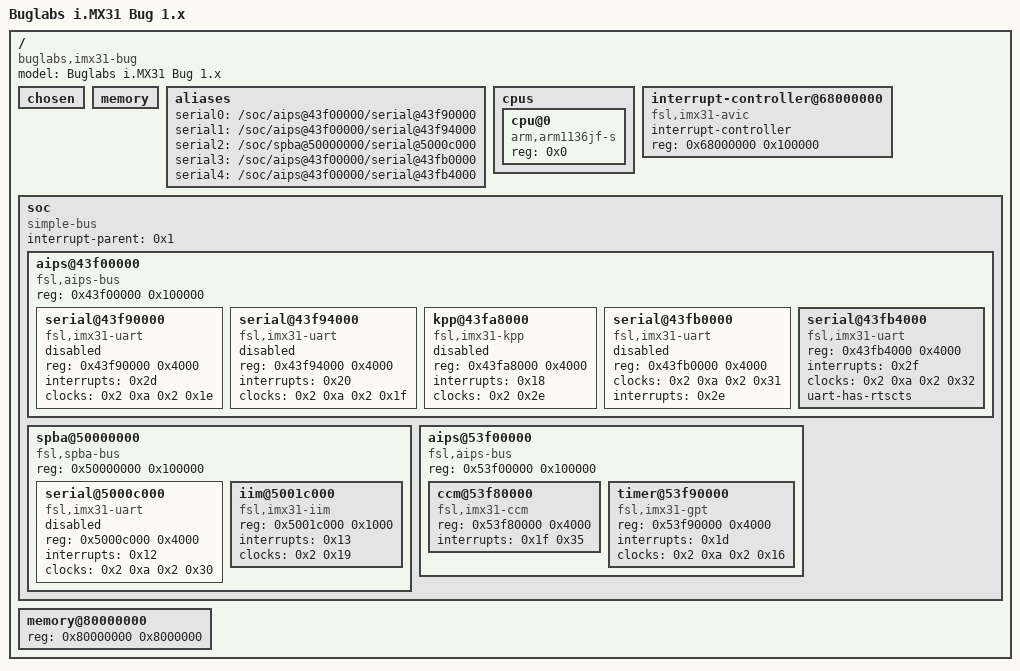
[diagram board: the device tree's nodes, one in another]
/dts-v1/;

/ {
	#address-cells = <0x1>;
	#size-cells = <0x1>;
	model = "Buglabs i.MX31 Bug 1.x";
	compatible = "buglabs,imx31-bug", "fsl,imx31";

	chosen {
	};

	memory {
		device_type = "memory";
	};

	aliases {
		serial0 = "/soc/aips@43f00000/serial@43f90000";
		serial1 = "/soc/aips@43f00000/serial@43f94000";
		serial2 = "/soc/spba@50000000/serial@5000c000";
		serial3 = "/soc/aips@43f00000/serial@43fb0000";
		serial4 = "/soc/aips@43f00000/serial@43fb4000";
	};

	cpus {
		#address-cells = <0x1>;
		#size-cells = <0x0>;

		cpu@0 {
			compatible = "arm,arm1136jf-s";
			device_type = "cpu";
			reg = <0x0>;
		};
	};

	interrupt-controller@68000000 {
		compatible = "fsl,imx31-avic", "fsl,avic";
		interrupt-controller;
		#interrupt-cells = <0x1>;
		reg = <0x68000000 0x100000>;
		phandle = <0x1>;
	};

	soc {
		#address-cells = <0x1>;
		#size-cells = <0x1>;
		compatible = "simple-bus";
		interrupt-parent = <0x1>;
		ranges;

		aips@43f00000 {
			compatible = "fsl,aips-bus", "simple-bus";
			#address-cells = <0x1>;
			#size-cells = <0x1>;
			reg = <0x43f00000 0x100000>;
			ranges;

			serial@43f90000 {
				compatible = "fsl,imx31-uart", "fsl,imx21-uart";
				reg = <0x43f90000 0x4000>;
				interrupts = <0x2d>;
				clocks = <0x2 0xa 0x2 0x1e>;
				clock-names = "ipg", "per";
				status = "disabled";
			};

			serial@43f94000 {
				compatible = "fsl,imx31-uart", "fsl,imx21-uart";
				reg = <0x43f94000 0x4000>;
				interrupts = <0x20>;
				clocks = <0x2 0xa 0x2 0x1f>;
				clock-names = "ipg", "per";
				status = "disabled";
			};

			kpp@43fa8000 {
				compatible = "fsl,imx31-kpp", "fsl,imx21-kpp";
				reg = <0x43fa8000 0x4000>;
				interrupts = <0x18>;
				clocks = <0x2 0x2e>;
				status = "disabled";
			};

			serial@43fb0000 {
				compatible = "fsl,imx31-uart", "fsl,imx21-uart";
				reg = <0x43fb0000 0x4000>;
				clocks = <0x2 0xa 0x2 0x31>;
				clock-names = "ipg", "per";
				interrupts = <0x2e>;
				status = "disabled";
			};

			serial@43fb4000 {
				compatible = "fsl,imx31-uart", "fsl,imx21-uart";
				reg = <0x43fb4000 0x4000>;
				interrupts = <0x2f>;
				clocks = <0x2 0xa 0x2 0x32>;
				clock-names = "ipg", "per";
				status = "okay";
				uart-has-rtscts;
			};
		};

		spba@50000000 {
			compatible = "fsl,spba-bus", "simple-bus";
			#address-cells = <0x1>;
			#size-cells = <0x1>;
			reg = <0x50000000 0x100000>;
			ranges;

			serial@5000c000 {
				compatible = "fsl,imx31-uart", "fsl,imx21-uart";
				reg = <0x5000c000 0x4000>;
				interrupts = <0x12>;
				clocks = <0x2 0xa 0x2 0x30>;
				clock-names = "ipg", "per";
				status = "disabled";
			};

			iim@5001c000 {
				compatible = "fsl,imx31-iim", "fsl,imx27-iim";
				reg = <0x5001c000 0x1000>;
				interrupts = <0x13>;
				clocks = <0x2 0x19>;
			};
		};

		aips@53f00000 {
			compatible = "fsl,aips-bus", "simple-bus";
			#address-cells = <0x1>;
			#size-cells = <0x1>;
			reg = <0x53f00000 0x100000>;
			ranges;

			ccm@53f80000 {
				compatible = "fsl,imx31-ccm";
				reg = <0x53f80000 0x4000>;
				interrupts = <0x1f 0x35>;
				#clock-cells = <0x1>;
				phandle = <0x2>;
			};

			timer@53f90000 {
				compatible = "fsl,imx31-gpt";
				reg = <0x53f90000 0x4000>;
				interrupts = <0x1d>;
				clocks = <0x2 0xa 0x2 0x16>;
				clock-names = "ipg", "per";
			};
		};
	};

	memory@80000000 {
		reg = <0x80000000 0x8000000>;
	};
};
